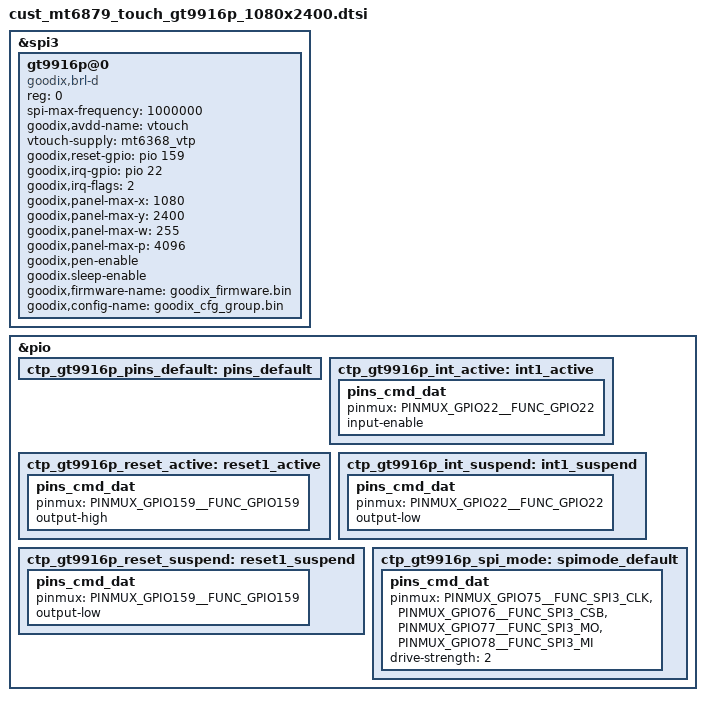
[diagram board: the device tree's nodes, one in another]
// SPDX-License-Identifier: (GPL-2.0 OR MIT)
/*
 * Copyright (C) 2020 MediaTek Inc.
 */

/* TOUCH start */

&spi3 {
	status = "okay";
	#address-cells = <1>;
	#size-cells = <0>;

	gt9916p@0 {
		compatible = "goodix,brl-d";
		reg = <0>; //Same as CS ID
		spi-max-frequency = <1000000>;

		goodix,avdd-name = "vtouch";
		vtouch-supply = <&mt6368_vtp>;

		goodix,reset-gpio = <&pio 159 0x0>;
		goodix,irq-gpio = <&pio 22 0x0>;
		goodix,irq-flags = <2>; /* 1:rising, 2:falling;*/
		goodix,panel-max-x = <1080>;
		goodix,panel-max-y = <2400>;
		goodix,panel-max-w = <255>;

		/* optional properties */
		goodix,panel-max-p = <4096>; /* max pressure that pen device supported */
		goodix,pen-enable; /* support active stylus device*/
		goodix.sleep-enable; /* enter sleep mode */
		goodix,firmware-name = "goodix_firmware.bin";
		goodix,config-name = "goodix_cfg_group.bin";

	};

};

&pio {
	ctp_gt9916p_pins_default: pins_default {
	};
	ctp_gt9916p_int_active: int1_active {
		pins_cmd_dat {
			pinmux = <PINMUX_GPIO22__FUNC_GPIO22>;
			input-enable;
		};
	};
	ctp_gt9916p_reset_active: reset1_active {
		pins_cmd_dat {
			pinmux = <PINMUX_GPIO159__FUNC_GPIO159>;
			output-high;
		};
	};
	ctp_gt9916p_int_suspend: int1_suspend {
		pins_cmd_dat {
			pinmux = <PINMUX_GPIO22__FUNC_GPIO22>;
			output-low;
		};
	};
	ctp_gt9916p_reset_suspend: reset1_suspend {
		pins_cmd_dat {
			pinmux = <PINMUX_GPIO159__FUNC_GPIO159>;
			output-low;
		};
	};
	ctp_gt9916p_spi_mode: spimode_default {
		pins_cmd_dat {
			pinmux = <PINMUX_GPIO75__FUNC_SPI3_CLK>,
				<PINMUX_GPIO76__FUNC_SPI3_CSB>,
				<PINMUX_GPIO77__FUNC_SPI3_MO>,
				<PINMUX_GPIO78__FUNC_SPI3_MI>;
			drive-strength = <2>;
		};
	};
};

/* TOUCH end */
